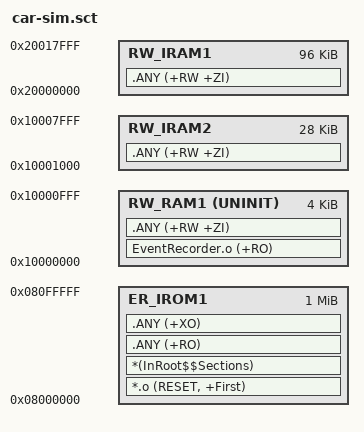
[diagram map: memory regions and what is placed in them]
; *************************************************************
; *** Scatter-Loading Description File generated by uVision ***
; *************************************************************

LR_IROM1 0x08000000 0x00100000  {    ; load region size_region
  ER_IROM1 0x08000000 0x00100000  {  ; load address = execution address
   *.o (RESET, +First)
   *(InRoot$$Sections)
   .ANY (+RO)
   .ANY (+XO)
  }
  RW_RAM1 0x10000000 UNINIT 0x00001000  {  ; RW data
    EventRecorder.o (+RO)
   .ANY (+RW +ZI)
  }
  RW_IRAM1 0x20000000 0x00018000  {
   .ANY (+RW +ZI)
  }
  RW_IRAM2 0x10001000 0x00007000  {
   .ANY (+RW +ZI)
  }
}

